# ET6801 register map
Vendor: ETMCU Inc.; File version: v0.0.1
CPU: CM7 r2p1, little endian, MPU, FPU, I-cache, D-cache, ITCM, DTCM, 4 interrupt priority bits
Registers are 32-bit, read-write, reset 0x0 unless marked. A register's access mark holds for its fields unless they carry their own. Offsets are from the block's base; [hi:lo] are bit positions.

## CAN0 (part 2 of 2) — Provide an overview of the purpose and functionality of the peripheral: mttcan_cfg
Base 0x40518000
Same registers: CAN1 0x40520000, CAN2 0x40528000
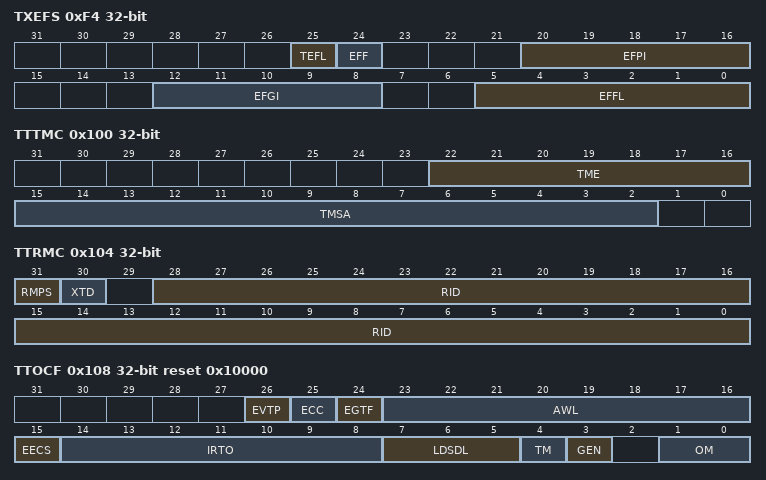
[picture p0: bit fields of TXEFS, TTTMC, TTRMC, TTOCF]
0xF4 TXEFS ro
  [25] TEFL — Tx Event FIFO Element Lost This bit is a copy of interrupt ﬂag IR.TEFL. When IR.TEFL is reset, this bit is also reset. 0= No Tx Event FIFO element lost 1= Tx Event FIFO element lost, also set after write attempt to Tx Event FIFO of size zero.
  [24] EFF — Event FIFO Full 0= Tx Event FIFO not full 1= Tx Event FIFO full
  [20:16] EFPI — Event FIFO Put Index Tx Event FIFO write index pointer, range 0 to 31.
  [12:8] EFGI — Event FIFO Get Index Tx Event FIFO read index pointer, range 0 to 31.
  [5:0] EFFL — Event FIFO Fill Level Number of elements stored in Tx Event FIFO, range 0 to 32.
0xF8 TXEFA ro
  [4:0] EFAI — Event FIFO Acknowledge Index After the Host has read an element or a sequence of elements from the Tx Event FIFO it has to write the index of the last element read from Tx Event FIFO to EFAI. This will set the Tx Event FIFO Get Index TXEFS.EFGI to EFAI + 1 and update the Event FIFO Fill Level TXEFS.EFFL.
0x100 TTTMC ro
  [22:16] TME — Trigger Memory Elements 0= No Trigger Memory 1-64= Number of Trigger Memory elements >64= Values greater than 64 are interpreted as 64
  [15:2] TMSA — Trigger Memory Start Address Start address of Trigger Memory in Message RAM (32-bit word address, see Figure 2).
0x104 TTRMC ro
  [31] RMPS — Reference Message Payload Select Ignored in case of time slaves. 0= Reference message has no additional payload 1= The following elements are taken from Tx Buffer 0: Message Marker MM, Event FIFO Control EFC, Data Length Code DLC, Data Bytes DB (Level 1: bytes 2-8, Level 0,2: bytes 5-8)
  [30] XTD — Extended Identiﬁer 0= 11-bit standard identiﬁer 1= 29-bit extended identiﬁer
  [28:0] RID — Reference Identiﬁer Identiﬁer transmitted with reference message and used for reference message ﬁltering. Standard or extended reference identiﬁer depending on bit XTD. A standard identiﬁer has to be written to ID[28:18].
0x108 TTOCF ro reset 0x10000
  [26] EVTP — Event Trigger Polarity 0= Rising edge trigger 1= Falling edge trigger
  [25] ECC — Enable Clock Calibration 0= Automatic clock calibration in TTCAN Level 0,2 is disabled 1= Automatic clock calibration in TTCAN Level 0,2 is enabled
  [24] EGTF — Enable Global Time Filtering 0= Global time ﬁltering in TTCAN Level 0,2 is disabled 1= Global time ﬁltering in TTCAN Level 0,2 is enabled
  [23:16] AWL — Application Watchdog Limit The application watchdog can be disabled by programming AWL to 0x00. 0x00-FF Maximum time after which the application has to serve the application watchdog. The application watchdog is incremented once each 256 NTUs.
  [15] EECS — Enable External Clock Synchronization If enabled, TUR conﬁguration (TURCF.NCL only) may be updated during TTCAN operation. 0= External clock synchronization in TTCAN Level 0,2 disabled 1= External clock synchronization in TTCAN Level 0,2 enabled
  [14:8] IRTO — Initial Reference Trigger Offset 0x00-7F Positive offset, range from 0 to 127
  [7:5] LDSDL — LD of Synchronization Deviation Limit The Synchronization Deviation Limit SDL is conﬁgured by its dual logarithm LDSDL with SDL = 2(LDSDL + 5) . It should not exceed the clock tolerance given by the CAN bit timing conﬁguration. 0x0-7 LD of Synchronization Deviation Limit (SDL ≤ 32...4096)
  [4] TM — Time Master 0= Time Master function disabled 1= Potential Time Master
  [3] GEN — Gap Enable 0= Strictly time-triggered operation 1= External event-synchronized time-triggered operation
  [1:0] OM — Operation Mode 00= Event-driven CAN communication, default 01= TTCAN level 1 10= TTCAN level 2 11= TTCAN level 0
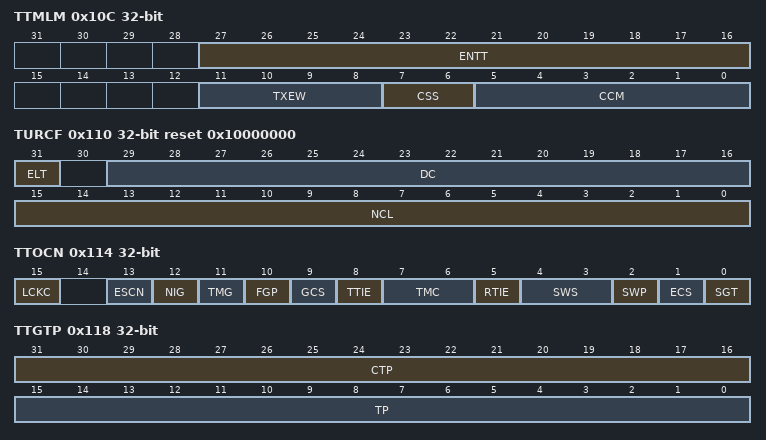
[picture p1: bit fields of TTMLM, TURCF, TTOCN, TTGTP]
0x10C TTMLM ro
  [27:16] ENTT — Expected Number of Tx Triggers 0x000-FFF Expected number of Tx Triggers in one Matrix Cycle
  [11:8] TXEW — Tx Enable Window 0x0-F Length of Tx enable window, 1-16 NTU cycles
  [7:6] CSS — Cycle Start Synchronization Enables sync pulse output at pin m_ttcan_soc. 00= No sync pulse 01= Sync pulse at start of basic cycle 10= Sync pulse at start of matrix cycle 11= Reserved
  [5:0] CCM — Cycle Count Max 0x00 1 Basic Cycle per Matrix Cycle 0x01 2 Basic Cycles per Matrix Cycle 0x03 4 Basic Cycles per Matrix Cycle 0x07 8 Basic Cycles per Matrix Cycle 0x0F 16 Basic Cycles per Matrix Cycle 0x1F 32 Basic Cycles per Matrix Cycle 0x3F 64 Basic Cycles per Matrix Cycle others Reserved
0x110 TURCF ro reset 0x10000000
  [31] ELT — Enable Local Time 0= Local time is stopped, default 1= Local time is enabled Note: Local time is started by setting ELT. It remains active until ELT is reset or until the next hardware reset. TURCF.DC is locked when TURCF.ELT = '1'. If ELT is written to '0', the readable value will stay at '1' until the new value has been synchronized into the CAN clock domain. During this time write access to the other bits of the register remains locked.
  [29:16] DC — Denominator Conﬁguration 0x0000 Illegal value 0x0001-3FFF Denominator Conﬁguration
  [15:0] NCL — Numerator Conﬁguration Low Write access to the TUR Numerator Conﬁguration Low is only possible during conﬁguration with TURCF.ELT = '0' or if TTOCF.EECS (external clock synchronization enabled) is set. When a new value for NCL is written outside TT Conﬁguration Mode, the new value takes effect when TTOST.WECS is cleared to '0'. NCL is locked TTOST.WECS is '1'. 0x0000-FFFF Numerator Conﬁguration Low
0x114 TTOCN
  [15] LCKC — TT Operation Control Register Locked Set by a write access to register TTOCN. Reset when the updated conﬁguration has been synchronized into the CAN clock domain. 0= Write access to TTOCN enabled 1= Write access to TTOCN locked
  [13] ESCN — External Synchronization Control If enabled the M_TTCAN synchronizes its cycle time phase to an external event signalled by a rising edge at pin m_ttcan_evt (see Section 4.11). 0= External synchronization disabled 1= External synchronization enabled
  [12] NIG — Next is Gap This bit can only be set when the M_TTCAN is the actual Time Master and when it is conﬁgured for external event-synchronized time-triggered operation (TTOCF.GEN = '1') 0= No action, reset by reception of any reference message 1= Transmit next reference message with Next_is_Gap = '1'
  [11] TMG — Time Mark Gap 0= Reset by each reference message 1= Next reference message started when Register Time Mark interrupt TTIR.RTMI is activated
  [10] FGP — Finish Gap Set by the CPU, reset by each reference message 0= No reference message requested 1= Application requested start of reference message
  [9] GCS — Gap Control Select 0= Gap control independent from m_ttcan_evt 1= Gap control by input pin m_ttcan_evt
  [8] TTIE — Trigger Time Mark Interrupt Pulse Enable External time mark events are conﬁgured by trigger memory element TMEX (see Section 2.4.7). A trigger time mark interrupt pulse is generated when the trigger memory element becomes active, and the M_TTCAN is in synchronization state In_Schedule or In_Gap. 0= Trigger Time Mark Interrupt output m_ttcan_tmp disabled 1= Trigger Time Mark Interrupt output m_ttcan_tmp enabled
  [7:6] TMC — Register Time Mark Compare 00= No Register Time Mark Interrupt generated 01= Register Time Mark Interrupt if Time Mark = cycle time 10= Register Time Mark Interrupt if Time Mark = local time 11= Register Time Mark Interrupt if Time Mark = global time
  [5] RTIE — Register Time Mark Interrupt Pulse Enable Register time mark interrupts are conﬁgured by register TTTMK. A register time mark interrupt pulse with the length of one NTU is generated when the time referenced by TTOCN.TMC (cycle, local, or global) equals TTTMK.TM, independent of the synchronization state. 0= Register Time Mark Interrupt output m_ttcan_rtp disabled 1= Register Time Mark Interrupt output m_ttcan_rtp enabled
  [4:3] SWS — Stop Watch Source 00= Stop Watch disabled 01= Actual value of cycle time is copied to TTCPT.SWV 10= Actual value of local time is copied to TTCPT.SWV 11= Actual value of global time is copied to TTCPT.SWV
  [2] SWP — Stop Watch Polarity 0= Rising edge trigger 1= Falling edge trigger
  [1] ECS — External Clock Synchronization Writing a '1' to ECS sets TTOST.WECS if the node is the actual Time Master. ECS is reset after one Host clock period. The external clock synchronization takes effect at the start of the next basic cycle.
  [0] SGT — Set Global time Writing a '1' to SGT sets TTOST.WGDT if the node is the actual Time Master. SGT is reset after one Host clock period. The global time preset takes effect when the node transmits the next reference message with the Master_Ref_Mark modiﬁed by the preset value written to TTGTP.
0x118 TTGTP
  [31:16] CTP — Cycle Time Target Phase CTP is write-protected while TTOCN.ESCN or TTOST.SPL are set (see Section 4.11). 0x0000-FFFF Deﬁnes target value of cycle time when a rising edge of m_ttcan_evt is expected
  [15:0] TP — Time Preset TP is write-protected while TTOST.WGTD is set. 0x0000-7FFF Next Master Reference Mark = Master Reference Mark + TP 0x8000 reserved 0x8001-FFFF Next Master Reference Mark = Master Reference Mark - (0x10000 - TP)
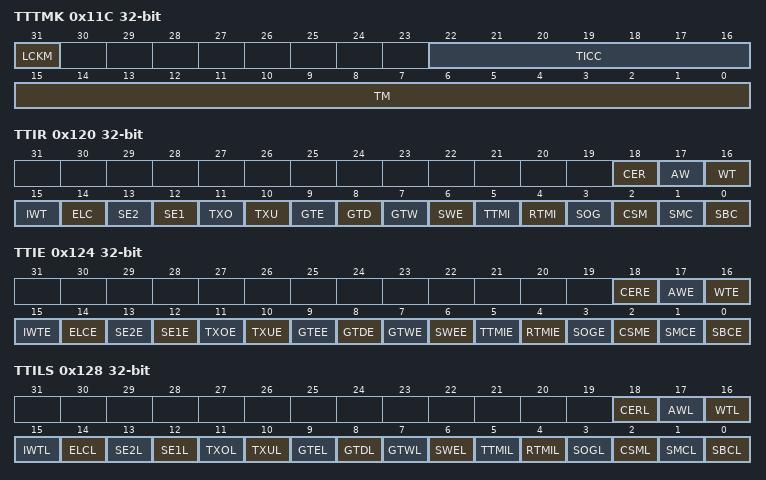
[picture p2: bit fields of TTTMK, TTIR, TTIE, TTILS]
0x11C TTTMK
  [31] LCKM — TT Time Mark Register Locked Always set by a write access to registers TTOCN. Set by write access to register TTTMK when TTOCN.TMC ≠ "00". Reset when the registers have been synchronized into the CAN clock domain. 0= Write access to TTTMK enabled 1= Write access to TTTMK locked
  [22:16] TICC — Time Mark Cycle Code Cycle count for which the time mark is valid. 0b000000x valid for all cycles 0b000001c valid every second cycle at cycle count mod2 = c 0b00001cc valid every fourth cycle at cycle count mod4 = cc 0b0001ccc valid every eighth cycle at cycle count mod8 = ccc 0b001cccc valid every sixteenth cycle at cycle count mod16 = cccc 0b01ccccc valid every thirty-second cycle at cycle count mod32 = ccccc 0b1cccccc valid every sixty-fourth cycle at cycle count mod64 = cccccc
  [15:0] TM — Time Mark 0x0000-FFFF Time Mark
0x120 TTIR
  [18] CER — Conﬁguration Error Trigger out of order. 0= No error found in trigger list 1= Error found in trigger list
  [17] AW — Application Watchdog 0= Application watchdog served in time 1= Application watchdog not served in time
  [16] WT — Watch Trigger 0= No missing reference message 1= Missing reference message (Level 0: cycle time 0xFF00)
  [15] IWT — Initialization Watch Trigger The initialization is restarted by resetting IWT. 0= No missing reference message during system startup 1= No system startup due to missing reference message
  [14] ELC — Error Level Changed Not set when error level changed during initialization. 0= No change in error level 1= Error level changed
  [13] SE2 — Scheduling Error 2 0= No scheduling error 2 1= Scheduling error 2 occurred
  [12] SE1 — Scheduling Error 1 0= No scheduling error 1 1= Scheduling error 1 occurred
  [11] TXO — Tx Count Overﬂow 0= Number of Tx Trigger as expected 1= More Tx trigger than expected in one matrix cycle
  [10] TXU — x Count Underﬂow 0= Number of Tx Trigger as expected 1= Less Tx trigger than expected in one matrix cycle
  [9] GTE — Global Time Error Synchronization deviation SD exceeds limit speciﬁed by TTOCF.LDSDL, TTCAN Level 0,2 only. 0= Synchronization deviation within limit 1= Synchronization deviation exceeded limit
  [8] GTD — Global Time Discontinuity 0= No discontinuity of global time 1= Discontinuity of global time
  [7] GTW — Global Time Wrap 0= No global time wrap occurred 1= Global time wrap from 0xFFFF to 0x0000 occurred
  [6] SWE — Stop Watch Event 0= No rising/falling edge at stop watch trigger pin m_ttcan_swt detected 1= Rising/falling edge at stop watch trigger pin m_ttcan_swt detected
  [5] TTMI — Trigger Time Mark Event Internal Internal time mark events are conﬁgured by trigger memory element TMIN (see Section 2.4.7). Set when the trigger memory element becomes active, and the M_TTCAN is in synchronization state In_Gap or In_Schedule. 0= Time mark not reached 1= Time mark reached (Level 0: cycle time TTOCF.IRTO • 0x200)
  [4] RTMI — Register Time Mark Interrupt Set when time referenced by TTOCN.TMC (cycle, local, or global) equals TTTMK.TM, independent of the synchronization state. 0= Time mark not reached 1= Time mark reached
  [3] SOG — Start of Gap 0= No reference message seen with Next_is_Gap bit set 1= Reference message with Next_is_Gap bit set becomes valid
  [2] CSM — Change of Synchronization Mode 0= No change in master to slave relation or schedule synchronization 1= Master to slave relation or schedule synchronization changed, also set when TTOST.SPL is reset
  [1] SMC — Start of Matrix Cycle 0= No Matrix Cycle started since bit has been reset 1= Matrix Cycle started
  [0] SBC — Start of Basic Cycle 0= No Basic Cycle started since bit has been reset 1= Basic Cycle started
0x124 TTIE
  [18] CERE — Conﬁguration Error Interrupt Enable
  [17] AWE — Application Watchdog Interrupt Enable
  [16] WTE — Watch Trigger Interrupt Enable
  [15] IWTE — Initialization Watch Trigger Interrupt Enable
  [14] ELCE — Change Error Level Interrupt Enable
  [13] SE2E — Scheduling Error 2 Interrupt Enable
  [12] SE1E — Scheduling Error 1 Interrupt Enable
  [11] TXOE — Tx Count Overﬂow Interrupt Enable
  [10] TXUE — Tx Count Underﬂow Interrupt Enable
  [9] GTEE — Global Time Error Interrupt Enable
  [8] GTDE — Global Time Discontinuity Interrupt Enable
  [7] GTWE — Global Time Wrap Interrupt Enable
  [6] SWEE — Stop Watch Event Interrupt Enable
  [5] TTMIE — Trigger Time Mark Event Internal Enable
  [4] RTMIE — Register Time Mark Interrupt Enable
  [3] SOGE — Start of Gap Interrupt Enable
  [2] CSME — Change of Synchronization Mode Interrupt Enable
  [1] SMCE — Start of Matrix Cycle Interrupt Enable
  [0] SBCE — Start of Basic Cycle Interrupt Enable
0x128 TTILS
  [18] CERL — Conﬁguration Error Interrupt Line
  [17] AWL — Application Watchdog Interrupt Line
  [16] WTL — Watch Trigger Interrupt Line
  [15] IWTL — Initialization Watch Trigger Interrupt Line
  [14] ELCL — Change Error Level Interrupt Line
  [13] SE2L — Scheduling Error 2 Interrupt Line
  [12] SE1L — Scheduling Error 1 Interrupt Line
  [11] TXOL — Tx Count Overﬂow Interrupt Line
  [10] TXUL — Tx Count Underﬂow Interrupt Line
  [9] GTEL — Global Time Error Interrupt Line
  [8] GTDL — Global Time Discontinuity Interrupt Line
  [7] GTWL — Global Time Wrap Interrupt Line
  [6] SWEL — Stop Watch Event Interrupt Line
  [5] TTMIL — Trigger Time Mark Event Internal Line
  [4] RTMIL — Register Time Mark Interrupt Line
  [3] SOGL — Start of Gap Interrupt Line
  [2] CSML — Change of Synchronization Mode Interrupt Line
  [1] SMCL — Start of Matrix Cycle Interrupt Line
  [0] SBCL — Start of Basic Cycle Interrupt Line
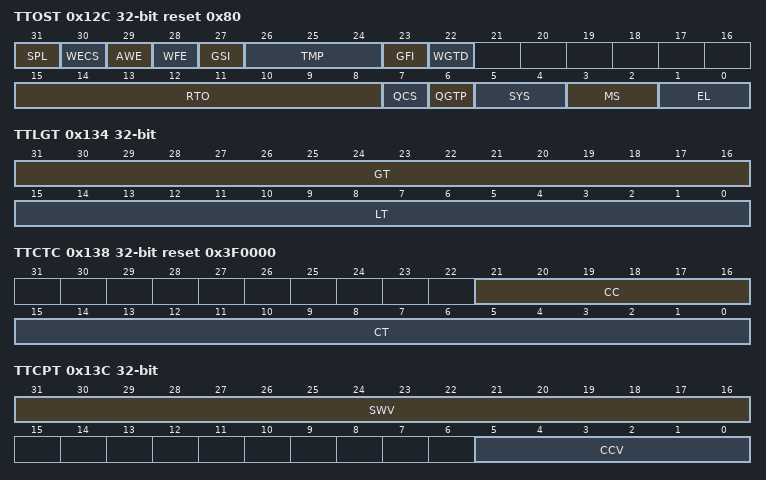
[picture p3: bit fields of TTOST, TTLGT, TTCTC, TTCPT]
0x12C TTOST ro reset 0x80
  [31] SPL — Schedule Phase Lock The bit is valid only when external synchronization is enabled (TTOCN.ESCN = '1'). In this case it signals that the difference between cycle time conﬁgured by TTGTP.CTP and the cycle time at the rising edge at pin m_ttcan_evt is less or equal 9 NTU (see Section 4.11). 0= Phase outside range 1= Phase inside range
  [30] WECS — Wait for External Clock Synchronization 0= No external clock synchronization pending 1= Node waits for external clock synchronization to take effect. The bit is reset at the start of the next basic cycle.
  [29] AWE — Application Watchdog Event The application watchdog is served by reading TTOST. When the watchdog is not served in time, bit AWE is set, all TTCAN communication is stopped, and the M_TTCAN is set into Bus Monitoring Mode. 0= Application Watchdog served in time 1= Failed to serve Application Watchdog in time
  [28] WFE — Wait for Event 0= No Gap announced, reset by a reference message with Next_is_Gap = '0' 1= Reference message with Next_is_Gap = '1' received
  [27] GSI — Gap Started Indicator 0= No Gap in schedule, reset by each reference message and for all time slaves 1= Gap time after Basic Cycle has started
  [26:24] TMP — Time Master Priority 0x0-7 Priority of actual Time Master
  [23] GFI — Gap Finished Indicator Set when the CPU writes TTOCN.FGP, or by a time mark interrupt if TMG = '1', or via input pin m_ttcan_evt if TTOCN.GCS = '1'. Not set by Ref_Trigger_Gap or when Gap is ﬁnished by another node sending a reference message. 0= Reset at the end of each reference message 1= Gap ﬁnished by M_TTCAN
  [22] WGTD — Wait for Global Time Discontinuity 0= No global time preset pending 1= Node waits for the global time preset to take effect. The bit is reset when the node has transmitted a reference message with Disc_Bit = '1' or after it received a reference message.
  [15:8] RTO — Reference Trigger Offset The Reference Trigger Offset value is a signed integer with a range from -127 (0x81) to 127 (0x7F). There is no notiﬁcation when the lower limit of -127 is reached. In case the M_TTCAN becomes Time Master (MS[1:0] = "11"), the reset of RTO is delayed due to synchronization between Host and CAN clock domain. For time slaves the value conﬁgured by TTOCF.IRTO is read. 0x00-FF Actual Reference Trigger offset value
  [7] QCS — Quality of Clock Speed Only relevant in TTCAN Level 0 and Level 2, otherwise ﬁxed to '1'. 0= Local clock speed not synchronized to Time Master clock speed 1= Synchronization Deviation ≤ SDL
  [6] QGTP — Quality of Global Time Phase Only relevant in TTCAN Level 0 and Level 2, otherwise ﬁxed to '0'. 0= Global time not valid 1= Global time in phase with Time Master
  [5:4] SYS — Synchronization State 00= Out of Synchronization 01= Synchronizing to TTCAN communication 10= Schedule suspended by Gap (In_Gap) 11= Synchronized to schedule (In_Schedule)
  [3:2] MS — Master State 00= Master_Off, no master properties relevant 01= Operating as Time Slave 10= Operating as Backup Time Master 11= Operating as current Time Master
  [1:0] EL — Error Level 00= Severity 0 - No Error 01= Severity 1 - Warning 10= Severity 2 - Error 11= Severity 3 - Severe Error
0x130 TURNA ro reset 0x10000
  [17:0] NAV — Numerator Actual Value ≤ 0x0EFFF reserved 0x0F000-20FFF Actual numerator value ≥ 0x21000 reserved
0x134 TTLGT ro
  [31:16] GT — Global Time Non-fractional part of the sum of the node's local time and its local offset (see Section 4.5). 0x0000-FFFF Global time value of TTCAN network
  [15:0] LT — Local Time Non-fractional part of local time, incremented once each local NTU (see Section 4.5). 0x0000-FFFF Local time value of TTCAN node
0x138 TTCTC ro reset 0x3F0000
  [21:16] CC — Cycle Count 0x00-3F Number of actual Basic Cycle in the System Matrix
  [15:0] CT — Cycle Time Non-fractional part of the difference of the node's local time and Ref_Mark (see Section 4.5). 0x0000-FFFF Cycle time value of TTCAN Basic Cycle
0x13C TTCPT ro
  [31:16] SWV — Stop Watch Value On a rising/falling edge (as conﬁgured via TTOCN.SWP) at the Stop Watch Trigger pin m_ttcan_swt, when TTOCN.SWS is ≠ "00" and TTIR.SWE is '0', the actual time value as selected by TTOCN.SWS (cycle, local, global) is copied to SWV and TTIR.SWE will be set to '1'. Capturing of the next stop watch value is enabled by resetting TTIR.SWE. 0x0000-FFFF Captured Stop Watch value
  [5:0] CCV — Cycle Count Value Cycle count value captured together with SWV. 0x00-3F Captured cycle count value
0x140 TTCSM ro
  [15:0] CSM — Cycle Sync Mark The Cycle Sync Mark is measured in cycle time. It is updated when the reference message becomes valid and retains its value until the next reference message becomes valid. 0x0000-FFFF Captured cycle time
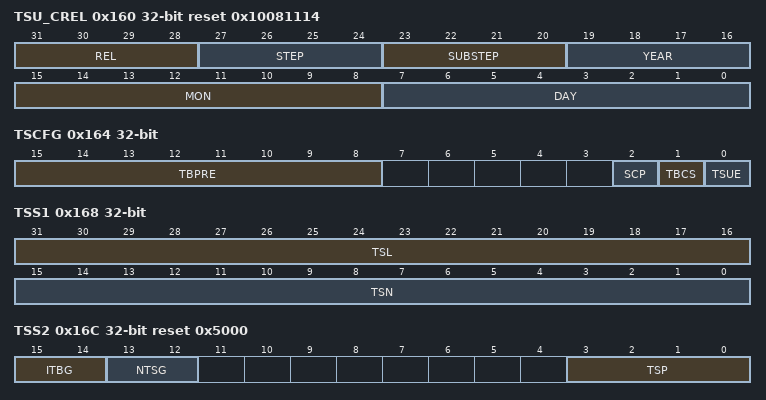
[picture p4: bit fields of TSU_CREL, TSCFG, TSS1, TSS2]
0x160 TSU_CREL ro reset 0x10081114
  [31:28] REL — Core Release One digit, BCD-coded
  [27:24] STEP — Step of Core Release One digit, BCD-coded
  [23:20] SUBSTEP — Sub-step of Core Release One digit, BCD-coded
  [19:16] YEAR — Timestamp Year One digit, BCD-coded. This field is set by generic parameter on synthesis.
  [15:8] MON — Timestamp Month Two digits, BCD-coded. This field is set by generic parameter on synthesis.
  [7:0] DAY — Timestamp Day Two digits, BCD-coded. This field is set by generic parameter on synthesis.
0x164 TSCFG ro
  [15:8] TBPRE — Timebase Prescaler 0x00 to 0xFF The value by which the oscillator frequency is divided for generating the timebase counter clock. Valid values for the Timebase Prescaler are 0 to 255. The actual interpretation by the hardware of this value is such that one more than the value programmed here is used. Affects only the TSU internal timebase. When the internal timebase is excluded by synthesis, TBPRE[7:0] is fixed to 0x00, the Timestamp Prescaler is not used.
  [2] SCP — Select Capturing Position With generic internal_tb_sof_g = 0 or 1 this bit is not available, reading always returns '0'. 0:Capture Timestamp at EOF 1:Capture Timestamp at SOF
  [1] TBCS — Timebase Counter Select When the internal timebase is excluded by synthesis, TBCS is fixed to '1'. 0:Timestamp value captured from internal timebase counter, ATB.TB[31:0] is the internal timbase counter 1:Timestamp value captured from input tsu_tbin[31:0], ATB.TB[31:0] is tsu_tbin[31:0]
  [0] TSUE — Timestamp Unit Enable 0:TSU disabled 1:TSU enabled
0x168 TSS1 ro
  [31:16] TSL — Timestamp Lost Each Timestamp register (TS0-TS15) is assigned one bit. The bits are set when the timestamp stored in the related Timestamp register was overwritten before it was read. Reading a Timestamp register resets the related bit.
  [15:0] TSN — Timestamp New Each Timestamp register (TS0-TS15) is assigned one bit. The bits are set when a timestamp was stored in the related Timestamp register. Reading a Timestamp register resets the related bit.
0x16C TSS2 ro reset 0x5000
  [15:14] ITBG — Internal Timebase and SOF select Generic Constant value of generic parameter internal_tb_sof_g. 00:no SOF option, no internal timebase 01:no SOF option, internal timebase (default) 10:SOF option, no internal timebase 11:SOF option, internal timebase
  [13:12] NTSG — Number of Timestamps Generic Constant value of generic parameter number_ts_g. 00:4 timestamp registers (TS0-TS3) 01:8 timestamp registers (default, TS0-TS7) 10:16 timestamp registers (TS0-TS15) 11:not a valid value
  [3:0] TSP — Timestamp Pointer The Timestamp Pointer is incremented by one each time a timestamp is captured. From its maximum value (3, 7, or 15 depending on number_ts_g), it is incremented to 0. Value also signalled on output m_can_tsp[3:0].
0x170 TS0 ro
  [31:0] TS0 — Timestamp Word TS0.
0x174 TS1 ro
  [31:0] TS1 — Timestamp Word TS1.
0x1B0 ATB ro
  [31:0] TB — Timebase for timestamp generation.
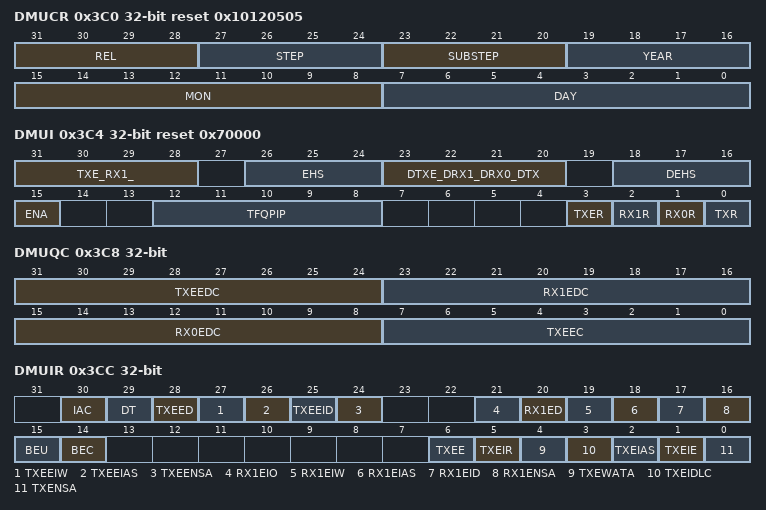
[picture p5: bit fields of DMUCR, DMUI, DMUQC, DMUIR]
0x3C0 DMUCR ro reset 0x10120505
  [31:28] REL — Core Release One digit, BCD-coded
  [27:24] STEP — Step of Core Release One digit, BCD-coded
  [23:20] SUBSTEP — Sub-step of Core Release One digit, BCD-coded
  [19:16] YEAR — Time Stamp Year One digit, BCD-coded. This field is set by generic parameter on DMU synthesis
  [15:8] MON — Time Stamp Month Two digits, BCD-coded. This field is set by generic parameter on DMU synthesis
  [7:0] DAY — Time Stamp Day Two digits, BCD-coded. This field is set by generic parameter on DMU synthesis
0x3C4 DMUI reset 0x70000
  [31:28] TXE_RX1_ RX0_TX — TXE, RX1, RX0, TX Actual DMU Element Service These four flags show which DMU Virtual Buffer is currently served, see Figure 1. Only one Virtual Buffer can be served at one time. The respective bit will be set by accessing the service's Start Address. The bit will be reset when service finishes after entering Element Handler State wait4sa (queueing successful) or recovery (queueing failure). 0 = DMU Virtual Buffer is currently not served 1 = DMU Virtual Buffer is currently served
  [26:24] EHS — Element Handler State Current state of the DMU Element Handler FSM, which controls the interaction with all DMU Elements, i.e. TX, RX0, RX1, TXE. 0 = wait4cce wait for bit M_CAN:CCCR.CCE getting zero 1 = wait4sa wait for Start Address 2 = wait4ta wait for Trigger Address 3 = transfer wait for transfer of Element word 4 = ack2mcan acknowledge to M_CAN 5 = recovery exception recovery 6,7 = unused
  [23:20] DTXE_DRX1_DRX0_DTX — DTXE, DRX1, DRX0, DTX Detect DMU Element Service Define the DMU Element Services used for debugging. Several services may be selected at one time. Interrupt flag DMUIR.DT gets active, when DMU Element Service and Element Handler State matches. 0 = Queueing of DMU Element does not activate interrupt flag 1 = Queueing of DMU Element will activate interrupt flag when DMUI.EHS = DMUI.DEHS
  [18:16] DEHS — Detect Element Handler State Define the DMU Element Handler state used for debugging. When state of the DMU Element Handler FSM reaches that state, and DMU Element Service was chosen for debugging (see bits 23:20) the interrupt flag DMUIR.DT will be activated. Reset value 7 = unused state. State encoding described in field description DMUI.EHS above.
  [15] ENA — DMU is enabled This flag shows the state of the DMU, i.e. enabled or disabled, depending on CCE mode of M_CAN, see 3.6. 0 = DMU is disabled 1 = DMU is enabled and can process DMA data
  [12:8] TFQPIP — TX FIFO/Queue Put Index Previous Put index, used by DMU Element Handler for previous enqueueing of a Tx Element. The debug section of Tx Element uses the previous put index for address redirection, to have access to the previously enqueued data.
  [3] TXER — TX Event Service Request line of DMU Logical value of the output signal dmu_txer, which requests a service from the external DMA to dequeue Tx event information with DMU TX Event Element. 0 = No TX Event DMA service requested 1 = TX Event DMA Service requested
  [2] RX1R — RX1 Service Request line of DMU Logical value of the output Signal dmu_rx1r, which requests a service from the external DMA to dequeue a CAN message with DMU RX1 Element. 0 = No RX1 DMA service requested 1 = RX1 DMA Service requested
  [1] RX0R — RX0 Service Request line of DMU Logical value of the output signal dmu_rx0r, which requests a service from the external DMA to dequeue a CAN message with DMU RX0 Element. 0 = No RX0 DMA service requested 1 = RX0 DMA Service requested
  [0] TXR — TX Service Request line of DMU Logical value of the output signal dmu_txr, which requests a service from the external DMA to enqueue a CAN message with DMU TX Element. 0 = No TX DMA service requested 1 = TX DMA Service requested
0x3C8 DMUQC ro
  [31:24] TXEEDC — TX Event Element Dequeueing Counter Increments on each successful dequeueing of a CAN TX Event information via DMU TX Event Element.
  [23:16] RX1EDC — RX1 Element Dequeueing Counter Increments on each successful dequeueing of a CAN RX message via DMU RX1 Element.
  [15:8] RX0EDC — RX0 Element Dequeueing Counter Increments on each successful dequeueing of a CAN RX message via DMU RX0 Element.
  [7:0] TXEEC — TX Element Enqueueing Counter Increments on each successful enqueueing of a CAN TX message via DMU TX Element.
0x3CC DMUIR ro
  [30] IAC — Illegal Access while in Configuration mode As long as the associated M_CAN is in CCE mode (M_CAN:CCCR.CCE = 1), the DMU is disabled and the Element Handler FSM is hold in state wait4cce, enqueueing and dequeueing is not possible, see 3.6. Any access to the DMU Virtual Buffers (TX, RX0, RX1, TX Event) sets the flag. 0 = No Illegal Access while CCE mode 1 = Illegal Access while CCE mode
  [29] DT — Debug Trigger In register DMUI the user can define a trigger condition for debugging, i.e. when a requested state of the DMU Element Handler is reached combined with the requested DMU Element Service. See register DMUI, bits 31:16. 0 = Debug point not reached 1 = Debug point reached
  [28] TXEED — TX Event Element Dequeued A successful dequeueing of a TX Event Element by the DMU sets this flag. 0 = No TX Event Element dequeued 1 = TX Event Element successfully dequeued
  [27] TXEEIW — TX Event Element Illegal Write All write accesses to the DMU TX Event Element are illegal. 0 = No write access detected 1 = Illegal write access to DMU TX Event Element detected, exception recovery started, see 3.4.
  [26] TXEEIAS — TX Event Element Illegal Access Sequence When the Start Address of the TX Event Element was accessed, the DMU expects the transfer of the TX Event Element. These read accesses to DMU Section have to be strictly linear to ascending and consecutive addresses until reaching the Trigger Address. This flag gets also active, when accessing another Virtual Buffer, before TX Event Element Service has been completed. 0 = No illegal addressing sequence detected 1 = Accesses are not strictly linear to ascending and consecutive addresses, exception recovery started, see 3.4.
  [25] TXEEID — TX Event Element Illegal Dequeueing A dequeueing of a TX Event Element with the DMU should only be started (reading from the Start Address of the TX Event Virtual Buffer) if this is requested by DMU Request signal dmu_txer. 0 = No illegal dequeueing 1 = Start of dequeueing without request detected, exception recovery started, see 3.4.
  [24] TXEENSA — TX Event Element Not Start Address An interaction with the TX Event Element Section of the DMU always has to start with a read access to the start address. This detector is only active when DMU is idle and thus awaits a start of a new service by an access to one of the Virtual Buffer's start addresses. 0 = No illegal read access 1 = Read from TX Event Element begins without using start address, exception recovery started, see 3.4.
  [21] RX1EIO — RX1 Element Illegal Overwrite by timestamp The configuration of the M_CAN Data Field Size must ensure, that the last word of a Rx Element is not used by SYNC message itself, in order to avoid DMU-internal overwrite with timestamp, see chapter 3.5.1. 0 = No illegal overwrite detected 1 = DMU has internally overwritten the last element word of a SYNC message
  [20] RX1ED — RX1 Element Dequeued A successful dequeueing of a Rx message with the DMU RX1 Element sets this flag. 0 = No Rx message dequeued 1 = Rx message successfully dequeued
  [19] RX1EIW — RX1 Element Illegal Write All write access to the DMU RX1 Element are illegal. 0 = No write access detected 1 = Illegal write access to DMU RX1 Element detected, exception recovery started, see 3.4.
  [18] RX1EIAS — RX1 Element Illegal Access Sequence When the start address of the RX1 Element was accessed, the DMU expects the transfer of the CAN message. These read accesses to DMU RX1 Element have to be strictly linear to ascending and consecutive addresses until reaching the Trigger Address. This flag gets also active, when accessing another Virtual Buffer, before RX1 Element service has been completed. 0 = No illegal addressing sequence detected 1 = Accesses are not strictly linear to ascending and consecutive addresses, exception recovery started, see 3.4.
  [17] RX1EID — RX1 Element Illegal Dequeueing A dequeueing of a Rx message with the Rx section of the DMU should only be started (reading from the start address of the RX1 Virtual Buffer) if this is requested by DMU Request signal dmu_rx1r. 0 = No illegal dequeueing 1 = Start of dequeueing without request detected, exception recovery started, see 3.4.
  [16] RX1ENSA — RX1 Element Not Start Address An interaction with the RX1 section of the DMU always has to start with a read access to the start address. This detector is only active when DMU is idle and thus awaits a start of a new service by an access to one of the Virtual Buffer's start addresses. 0 = No illegal read access 1 = Read from RX1 Element begins without using start address, exception recovery started, see 3.4.
  [15] BEU — Bit Error Uncorrected On read accesses to the MRAM via DMU, an optional external parity/ECC logic attached to the MRAM can detect bit errors. 0 = No bit error detected when reading from Message RAM 1 = Uncorrected bit error detected
  [14] BEC — Bit Error Corrected On read accesses to the MRAM via DMU, an optional external ECC logic attached to the MRAM can detect and correct bit errors. 0 = No bit error detected when reading from Message RAM 1 = Bit error detected and corrected
  [6] TXEE — TX Element Enqueued A successful enqueueing of a Tx message with the DMU TX Element section sets this flag. 0 = No Tx message enqueued 1 = Tx message successfully enqueued
  [5] TXEIR — TX Element Illegal Read All read accesses to the DMU TX Element section are illegal and return undefined read data. 0 = No read access 1 = Illegal read access to DMU TX Element section detected, exception recovery started, see 3.4.
  [4] TXEWATA — TX Element Write After Trigger Address The DMU expects that only the active words of a TX Element are transferred, see 3.1.1. In some applications, the message transfer with dynamic length, controlled by DLC is not applicable. In such a case, the DMA controller may transfer (write) the maximum size Tx Buffer element, independent of the actual length of the contained message. The DMU tolerates this by discarding these accesses and setting this flag. This exception handling will be finished with accessing an address other than between Trigger Address and last address of TX Element section or on occurrence of an access error, which normally aborts a pending enqueueing. 0 = No write after Trigger Address 1 = Write after Trigger address detected
  [3] TXEIDLC — TX Element Illegal DLC In the case that the DLC written to TX Element indicates a message that is larger than the configuration of M_CAN's Tx Buffer element size (M_CAN:TXESC.TBDS), the DMU aborts the enqueueing. Example: Tx Buffer element size is set to 8 byte data fields (M_CAN:TXESC.TBDS = 0). The DLC in T1 written to DMU TX Element indicates a CAN message with 64 byte data field. 0 = No illegal DLC detected 1 = DLC exceeds Tx Buffer element size of M_CAN, exception recovery started, see 3.4.
  [2] TXEIAS — TX Element Illegal Access Sequence By accessing the start address of the TX Element, the DMU awaits the transfer of the CAN message. These write accesses to DMU TX Element have to be strictly linear to ascending and consecutive addresses until reaching the last word of the CAN message. This flag gets also active, when accessing another Virtual Buffer, before TX Element service has been completed. 0 = No illegal addressing sequence detected 1 = Accesses are not strictly linear to ascending and consecutive addresses, exception recovery started, see 3.4.
  [1] TXEIE — TX Element Illegal Enqueueing An enqueueing of a Tx message with the TX Section of the DMU should only be started (writing to the start address of the TX Section) if this is requested by DMU Request signal dmu_txr. 0 = No illegal enqueueing 1 = Start of enqueueing without request detected, exception recovery started, see 3.4.
  [0] TXENSA — TX Element Not Start Address An interaction with the TX Section of the DMU always has to start with a write access to the start address. This detector is only active when DMU is idle and thus awaits a start of a new service by an access to one of the Virtual Buffer's start addresses. 0 = No illegal write access 1 = Write to TX Element begins without using start address, exception recovery started, see 3.4.
0x3D0 DMUIE
  [0] TXENSAE — TX Element Not Start Address Enable 0 = Flag DMUIR.TXENSA does not activate the interrupt line dmu_int 1 = If DMUIR.TXENSA = '1' the interrupt line dmu_int will be activated
0x3D4 DMUC ro
  [0] TTS — Transfer Timestamp The DMU supports the transfer of TSU timestamps via DMU Virtual Buffer for RX0, RX1 and TX Event Elements, see chapter 3.5. This flag is kept to '0' if M_CAN:CCCR.UTSU = '0', see [1]. 0 = No timestamp will be transferred via DMU Virtual Buffer 1 = Timestamp of message will be transferred from TSU via DMU Virtual Buffer
